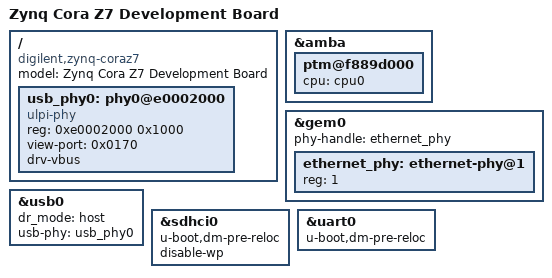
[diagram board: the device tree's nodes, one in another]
#include "zynq-7000.dtsi"
#include "include/dt-bindings/gpio/gpio.h"

/ {
	model = "Zynq Cora Z7 Development Board";
	compatible = "digilent,zynq-coraz7", "xlnx,zynq-7000";

	usb_phy0: phy0@e0002000 {
		compatible = "ulpi-phy";
		#phy-cells = <0>;
		reg = <0xe0002000 0x1000>;
		view-port = <0x0170>;
		drv-vbus;
	};


};

&amba {
	ptm@f889d000 {
		cpu = <&cpu0>;
	};
};

&gem0 {
	phy-handle = <&ethernet_phy>;
/*	phy-reset-gpio = <&gpio0 GPIO_ACTIVE_LOW>;
	phy-reset-active-low;	
	phy-reset-duration = <10>;  */
	ethernet_phy: ethernet-phy@1 { /* rtl8211e-vl */
		reg = <1>;
		device_type = "ethernet-phy";
	};
};
&usb0 {	
	dr_mode = "host";
	usb-phy = <&usb_phy0>;
};
&sdhci0 {
	u-boot,dm-pre-reloc;
	disable-wp;
};
&uart0 {
	u-boot,dm-pre-reloc;
};
